# max32665 register map
Vendor: Maxim-Integrated; Series: ARMCM3; File version: 1.0
CPU: CM4 r2p1, little endian, MPU, FPU, 3 interrupt priority bits
Registers are 32-bit, read-write, reset 0x0 unless marked. A register's access mark holds for its fields unless they carry their own. Offsets are from the block's base; [hi:lo] are bit positions.

## HTMR — High Speed Timer Module.
Base 0x4001B000
Same registers: HTMR1 0x4001C000
0x00 SEC reset not defined — HTimer Long-Interval Counter. This register contains the 32 most significant bits of the counter.
  [30:0] RTS — HTimer Long Interval Counter.
0x04 SSEC reset not defined — HTimer Short Interval Counter. This counter ticks ever t_htclk (16.48uS). HTIMER_SEC is incremented when this register rolls over from 0xFF to 0x00.
  [7:0] RTSS — HTimer Short Interval Counter.
0x08 RAS reset not defined — Long Interval Alarm.
  [19:0] RAS — HTimer Long Interval Alarm. An Alarm is triggered when this value matches HTIMER_SEC[19:0]
0x0C RSSA reset not defined — HTimer Short Interval Alarm. This register contains the reload value for the short interval alarm, HTIMER_CTRL.alarm_ss_fl is raised on rollover.
  [31:0] RSSA — This register contains the reload value for the short interval alarm.
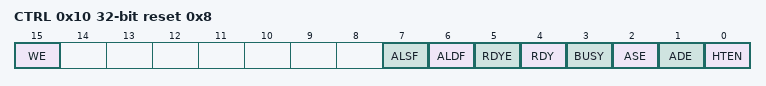
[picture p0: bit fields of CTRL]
0x10 CTRL reset 0x8 (reset mask 0xFFFFFF38) — HTimer Control Register.
  [15] WE — Write Enable. This register bit serves as a protection mechanism against unintentional writes to critical HTimer bits.
    0=dis (Not active); 1=en (Active)
  [7] ALSF ro — Short Interval Alarm Interrupt Flag. This alarm is qualified as wake-up source to the processor.
    0=inactive (Not active); 1=Pending (Active)
  [6] ALDF ro — Long Interval Alarm Interrupt Flag. This alarm is qualified as wake-up source to the processor.
    0=inactive (Not active); 1=pending (Active)
  [5] RDYE — HTimer Ready Interrupt Enable.
    0=dis (Disable.); 1=en (Enable.)
  [4] RDY — HTimer Ready. This bit is set to 1 by hardware when the HTimer count registers update. It can be cleared to 0 by software at any time. It will also be cleared to 0 by hardware just prior to an update of the HTimer count register.
    0=busy (Register has not updated.); 1=ready
  [3] BUSY ro — HTimer Busy. This bit is set to 1 by hardware when changes to HTimer registers required a synchronized version of the register to be in place. This bit is automatically cleared by hardware.
    0=idle; 1=busy
  [2] ASE — Short Interval Alarm Interrupt Enable. Change to this bit is effective only after BUSY is cleared from 1 to 0.
    0=dis (Disable.); 1=en (Enable.)
  [1] ADE — Long Interval Alarm Interrupt Enable. Change to this bit is effective only after BUSY is cleared from 1 to 0.
    0=dis (Disable.); 1=en (Enable.)
  [0] HTEN — HTimer Enable. This bit enables the Real Time Clock. This bit can only be written when WE=1 and BUSY =0. Change to this bit is effective only after BUSY is cleared from 1 to 0.
    0=dis (Disable.); 1=en (Enable.)

## ICC0 — Instruction Cache Controller Registers
Base 0x4002A000
Same registers: ICC1 0x4002AC000
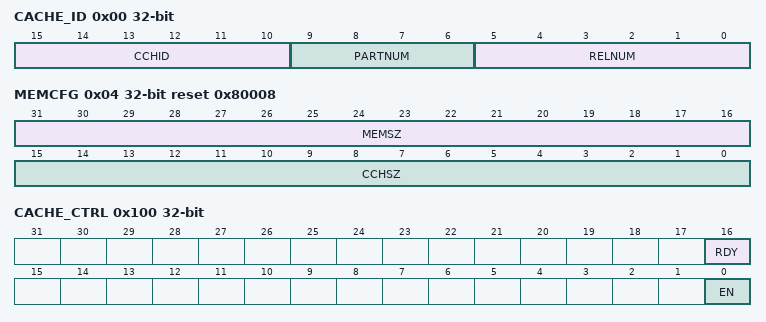
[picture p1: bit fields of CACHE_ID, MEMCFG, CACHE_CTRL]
0x00 CACHE_ID ro
  [15:10] CCHID — Cache ID. This field reflects the value of the C_ID_CACHEID configuration parameter.
  [9:6] PARTNUM — Part Number. This field reflects the value of C_ID_PART_NUMBER configuration parameter.
  [5:0] RELNUM — Release Number. Identifies the RTL release version.
0x04 MEMCFG ro reset 0x80008 — Memory Configuration Register.
  [31:16] MEMSZ — Main Memory Size. Indicates the total size, in units of 128 Kbytes, of code memory accessible to the cache controller.
  [15:0] CCHSZ — Cache Size. Indicates total size in Kbytes of cache.
0x100 CACHE_CTRL — Cache Control and Status Register.
  [16] RDY ro — Cache Ready flag. Cleared by hardware when at any time the cache as a whole is invalidated (including a system reset). When this bit is 0, the cache is effectively in bypass mode (instruction fetches will come from main memory or from the line fill buffer). Set by hardware when the invalidate operation is complete and the cache is ready.
    0=notReady; 1=ready
  [0] EN — Cache Enable. Controls whether the cache is bypassed or is in use. Changing the state of this bit will cause the instruction cache to be flushed and its contents invalidated.
    0=dis (Cache Bypassed. Instruction data is stored in the line fill buffer but is not written to main cache memory array.); 1=en (Cache Enabled.)
0x700 INVALIDATE — Invalidate All Registers.
  [31:0] INVALID — Invalidate.
